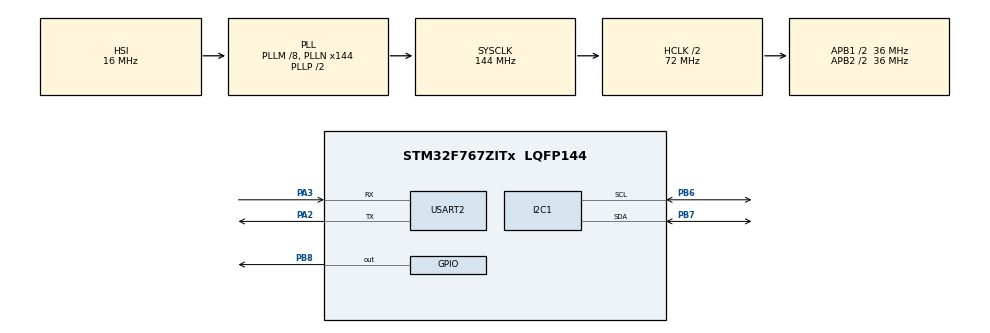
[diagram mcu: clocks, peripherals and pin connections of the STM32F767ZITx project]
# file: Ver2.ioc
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I2C1.Timing=0x00808CD2
Mcu.Family=STM32F7
Mcu.Name=STM32F767ZITx
Mcu.Package=LQFP144
NVIC.PriorityGroup=NVIC_PRIORITYGROUP_4
PA13.Mode=Serial_Wire
PA13.Signal=SYS_JTMS-SWDIO
PA14.Mode=Serial_Wire
PA14.Signal=SYS_JTCK-SWCLK
PA2.Mode=Asynchronous
PA2.Signal=USART2_TX
PA3.Mode=Asynchronous
PA3.Signal=USART2_RX
PB6.Mode=I2C
PB6.Signal=I2C1_SCL
PB7.Mode=I2C
PB7.Signal=I2C1_SDA
PB8.GPIO_FM8=__NULL
PB8.GPIO_ModeDefaultOutputPP=GPIO_MODE_OUTPUT_OD
PB8.GPIO_PuPd=GPIO_NOPULL
PB8.Signal=GPIO_Output
PC14/OSC32_IN.Mode=LSE-External-Oscillator
PC14/OSC32_IN.Signal=RCC_OSC32_IN
PC15/OSC32_OUT.Mode=LSE-External-Oscillator
PC15/OSC32_OUT.Signal=RCC_OSC32_OUT
PH0/OSC_IN.Mode=HSE-External-Oscillator
PH0/OSC_IN.Signal=RCC_OSC_IN
PH1/OSC_OUT.Mode=HSE-External-Oscillator
PH1/OSC_OUT.Signal=RCC_OSC_OUT
ProjectManager.HeapSize=0x200
ProjectManager.StackSize=0x400
ProjectManager.TargetToolchain=STM32CubeIDE
RCC.AHBCLKDivider=RCC_SYSCLK_DIV2
RCC.AHBFreq_Value=72000000
RCC.APB1CLKDivider=RCC_HCLK_DIV2
RCC.APB1Freq_Value=36000000
RCC.APB1TimFreq_Value=72000000
RCC.APB2CLKDivider=RCC_HCLK_DIV2
RCC.APB2Freq_Value=36000000
RCC.APB2TimFreq_Value=72000000
RCC.CortexFreq_Value=72000000
RCC.HCLKFreq_Value=72000000
RCC.HSE_VALUE=25000000
RCC.HSI_VALUE=16000000
RCC.PLLM=8
RCC.PLLN=144
RCC.SYSCLKFreq_VALUE=144000000
RCC.SYSCLKSource=RCC_SYSCLKSOURCE_PLLCLK
RCC.USBFreq_Value=144000000
RCC.VCOOutputFreq_Value=288000000
TIM1.Prescaler=72-1
TIM1.RepetitionCounter=1
TIM1.TIM_MasterSlaveMode=TIM_MASTERSLAVEMODE_DISABLE
USART2.OneBitSampling=UART_ONE_BIT_SAMPLE_ENABLE
USART2.VirtualMode-Asynchronous=VM_ASYNC
VP_TIM1_VS_ClockSourceINT.Mode=Internal
board=custom

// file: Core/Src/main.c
/* USER CODE BEGIN Header */
/**
  ******************************************************************************
  * @file           : main.c
  * @brief          : Main program body
  ******************************************************************************
  * @attention
  *
  * Copyright (c) 2023 STMicroelectronics.
  * All rights reserved.
  *
  * This software is licensed under terms that can be found in the LICENSE file
  * in the root directory of this software component.
  * If no LICENSE file comes with this software, it is provided AS-IS.
  *
  ******************************************************************************
  */
/* USER CODE END Header */
#include "main.h"
#include "i2c.h"
#include "tim.h"
#include "usart.h"
#include "gpio.h"

/* USER CODE BEGIN Includes */
#include "ds18b20.h"
/* USER CODE END Includes */

/* USER CODE BEGIN PV */
short temperature;
/* USER CODE END PV */

void SystemClock_Config(void);

int main(void)
{

  /* MCU Configuration--------------------------------------------------------*/

  /* Reset of all peripherals, Initializes the Flash interface and the Systick. */
  HAL_Init();

  /* Configure the system clock */
  SystemClock_Config();

  /* Initialize all configured peripherals */
  MX_GPIO_Init();
  MX_USART2_UART_Init();
  MX_I2C1_Init();
  MX_TIM1_Init();

  /* Infinite loop */
  while (1)
  {

    /* USER CODE BEGIN 3 */
		temperature = DS18B20_Get_Temp();
		if(temperature < 0)
			printf("TEMP -%d ℃\r\n",temperature/10);
		else
			printf("TEMP %d ℃\r\n",temperature/10);
		HAL_Delay(500);

}

  /* USER CODE END 3 */
}

void SystemClock_Config(void)
{
  RCC_OscInitTypeDef RCC_OscInitStruct = {0};
  RCC_ClkInitTypeDef RCC_ClkInitStruct = {0};

  /** Configure LSE Drive Capability
  */
  HAL_PWR_EnableBkUpAccess();

  /** Configure the main internal regulator output voltage
  */
  __HAL_RCC_PWR_CLK_ENABLE();
  __HAL_PWR_VOLTAGESCALING_CONFIG(PWR_REGULATOR_VOLTAGE_SCALE3);

  /** Initializes the RCC Oscillators according to the specified parameters
  * in the RCC_OscInitTypeDef structure.
  */
  RCC_OscInitStruct.OscillatorType = RCC_OSCILLATORTYPE_HSI;
  RCC_OscInitStruct.HSIState = RCC_HSI_ON;
  RCC_OscInitStruct.HSICalibrationValue = RCC_HSICALIBRATION_DEFAULT;
  RCC_OscInitStruct.PLL.PLLState = RCC_PLL_ON;
  RCC_OscInitStruct.PLL.PLLSource = RCC_PLLSOURCE_HSI;
  RCC_OscInitStruct.PLL.PLLM = 8;
  RCC_OscInitStruct.PLL.PLLN = 144;
  RCC_OscInitStruct.PLL.PLLP = RCC_PLLP_DIV2;
  RCC_OscInitStruct.PLL.PLLQ = 2;
  RCC_OscInitStruct.PLL.PLLR = 2;
  if (HAL_RCC_OscConfig(&RCC_OscInitStruct) != HAL_OK)
  {
    Error_Handler();
  }

  /** Initializes the CPU, AHB and APB buses clocks
  */
  RCC_ClkInitStruct.ClockType = RCC_CLOCKTYPE_HCLK|RCC_CLOCKTYPE_SYSCLK
                              |RCC_CLOCKTYPE_PCLK1|RCC_CLOCKTYPE_PCLK2;
  RCC_ClkInitStruct.SYSCLKSource = RCC_SYSCLKSOURCE_PLLCLK;
  RCC_ClkInitStruct.AHBCLKDivider = RCC_SYSCLK_DIV2;
  RCC_ClkInitStruct.APB1CLKDivider = RCC_HCLK_DIV2;
  RCC_ClkInitStruct.APB2CLKDivider = RCC_HCLK_DIV2;

  if (HAL_RCC_ClockConfig(&RCC_ClkInitStruct, FLASH_LATENCY_2) != HAL_OK)
  {
    Error_Handler();
  }
}

/* USER CODE BEGIN 4 */
/**Configure the Systick interrupt time
*/

/* USER CODE END 4 */

void Error_Handler(void)
{
  __disable_irq();
  while (1)
  {
  }
}
